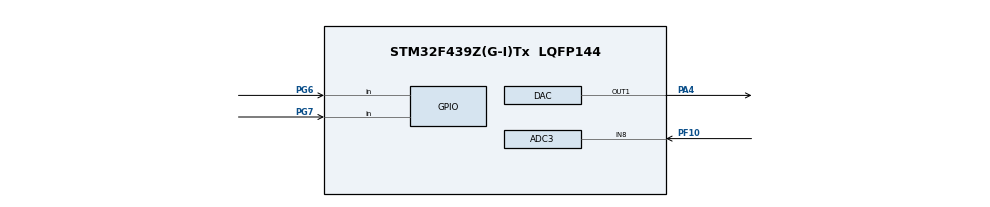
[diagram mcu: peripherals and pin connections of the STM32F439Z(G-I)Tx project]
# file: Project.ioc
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ADC3.Channel-0\#ChannelRegularConversion=ADC_CHANNEL_8
ADC3.ClockPrescaler=ADC_CLOCKPRESCALER_PCLK_DIV2
ADC3.ContinuousConvMode=ENABLE
ADC3.DMAContinuousRequests=ENABLE
ADC3.DataAlign=ADC_DATAALIGN_RIGHT
ADC3.DiscontinuousConvMode=DISABLE
ADC3.EOCSelection=EOC_SINGLE_CONV
ADC3.EnableAnalogWatchDog=false
ADC3.ExternalTrigConvEdge=ADC_EXTERNALTRIGCONVEDGE_NONE
ADC3.InjNumberOfConversion=0
ADC3.NbrOfConversion=1
ADC3.NbrOfConversionFlag=1
ADC3.Rank-0\#ChannelRegularConversion=1
ADC3.Resolution=ADC_RESOLUTION12b
ADC3.SamplingTime-0\#ChannelRegularConversion=ADC_SAMPLETIME_3CYCLES
ADC3.ScanConvMode=DISABLE
DAC.DAC_Trigger=DAC_TRIGGER_NONE
Dma.ADC3.0.Channel=DMA_CHANNEL_2
Dma.ADC3.0.Direction=DMA_PERIPH_TO_MEMORY
Dma.ADC3.0.FIFOMode=DMA_FIFOMODE_DISABLE
Dma.ADC3.0.FIFOThreshold=DMA_FIFO_THRESHOLD_FULL
Dma.ADC3.0.Instance=DMA2_Stream0
Dma.ADC3.0.MemBurst=DMA_MBURST_SINGLE
Dma.ADC3.0.MemDataAlignment=DMA_MDATAALIGN_WORD
Dma.ADC3.0.MemInc=DMA_MINC_DISABLE
Dma.ADC3.0.Mode=DMA_CIRCULAR
Dma.ADC3.0.PeriphBurst=DMA_PBURST_SINGLE
Dma.ADC3.0.PeriphDataAlignment=DMA_PDATAALIGN_WORD
Dma.ADC3.0.PeriphInc=DMA_PINC_DISABLE
Dma.ADC3.0.Priority=DMA_PRIORITY_HIGH
Dma.Request0=ADC3
Mcu.Family=STM32F4
Mcu.Name=STM32F439Z(G-I)Tx
Mcu.Package=LQFP144
NVIC.ADC_IRQn=true\:1\:0\:true
NVIC.DMA2_Stream0_IRQn=true\:3\:0\:true
NVIC.PriorityGroup=NVIC_PRIORITYGROUP_4
NVIC.TIM6_DAC_IRQn=true\:2\:0\:true
PA4.Signal=COMP_DAC1_group
PF10.Mode=IN8
PF10.Signal=ADC3_IN8
PG6.Signal=GPIO_Input
PG7.Signal=GPIO_Input
ProjectManager.TargetToolchain=EWARM
RCC.AHBFreq_Value=16000000
RCC.APB1Freq_Value=16000000
RCC.APB2Freq_Value=16000000
RCC.CortexFreq_Value=16000000
RCC.HSE_VALUE=25000000
RCC.HSI_VALUE=16000000
RCC.LSE_VALUE=32768
RCC.SYSCLKFreq_VALUE=16000000
RCC.VCOOutputFreq_Value=192000000
SH.COMP_DAC1_group.0=DAC_OUT1,DAC_OUT1
board=Project

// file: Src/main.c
/**
  ******************************************************************************
  * File Name          : main.c
  * Description        : Main program body
  ******************************************************************************
  *
  * COPYRIGHT(c) 2015 STMicroelectronics
  *
  * Redistribution and use in source and binary forms, with or without modification,
  * are permitted provided that the following conditions are met:
  *   1. Redistributions of source code must retain the above copyright notice,
  *      this list of conditions and the following disclaimer.
  *   2. Redistributions in binary form must reproduce the above copyright notice,
  *      this list of conditions and the following disclaimer in the documentation
  *      and/or other materials provided with the distribution.
  *   3. Neither the name of STMicroelectronics nor the names of its contributors
  *      may be used to endorse or promote products derived from this software
  *      without specific prior written permission.
  *
  * THIS SOFTWARE IS PROVIDED BY THE COPYRIGHT HOLDERS AND CONTRIBUTORS "AS IS"
  * AND ANY EXPRESS OR IMPLIED WARRANTIES, INCLUDING, BUT NOT LIMITED TO, THE
  * IMPLIED WARRANTIES OF MERCHANTABILITY AND FITNESS FOR A PARTICULAR PURPOSE ARE
  * DISCLAIMED. IN NO EVENT SHALL THE COPYRIGHT HOLDER OR CONTRIBUTORS BE LIABLE
  * FOR ANY DIRECT, INDIRECT, INCIDENTAL, SPECIAL, EXEMPLARY, OR CONSEQUENTIAL
  * DAMAGES (INCLUDING, BUT NOT LIMITED TO, PROCUREMENT OF SUBSTITUTE GOODS OR
  * SERVICES; LOSS OF USE, DATA, OR PROFITS; OR BUSINESS INTERRUPTION) HOWEVER
  * CAUSED AND ON ANY THEORY OF LIABILITY, WHETHER IN CONTRACT, STRICT LIABILITY,
  * OR TORT (INCLUDING NEGLIGENCE OR OTHERWISE) ARISING IN ANY WAY OUT OF THE USE
  * OF THIS SOFTWARE, EVEN IF ADVISED OF THE POSSIBILITY OF SUCH DAMAGE.
  *
  ******************************************************************************
  */
#include "stm32f4xx_hal.h"

ADC_HandleTypeDef hadc3;
DMA_HandleTypeDef hdma_adc3;

DAC_HandleTypeDef hdac;

/* USER CODE BEGIN PV */
/* Private variables ---------------------------------------------------------*/

/* USER CODE END PV */

void SystemClock_Config(void);
static void MX_GPIO_Init(void);
static void MX_DMA_Init(void);
static void MX_ADC3_Init(void);
static void MX_DAC_Init(void);

/* USER CODE BEGIN PFP */
/* Private function prototypes -----------------------------------------------*/

/* USER CODE END PFP */

int main(void)
{

  /* MCU Configuration----------------------------------------------------------*/

  /* Reset of all peripherals, Initializes the Flash interface and the Systick. */
  HAL_Init();

  /* Configure the system clock */
  SystemClock_Config();

  /* Initialize all configured peripherals */
  MX_GPIO_Init();
  MX_DMA_Init();
  MX_ADC3_Init();
  MX_DAC_Init();

  /* USER CODE BEGIN 2 */
  HAL_ADC_Start_DMA(&hadc3,(uint32_t*)0x40007408, 32);
  HAL_DAC_Start(&hdac, DAC_CHANNEL_1);

  /* USER CODE END 2 */

  /* Infinite loop */
  while (1)
  {

  }

}

/** System Clock Configuration
*/
void SystemClock_Config(void)
{

  RCC_OscInitTypeDef RCC_OscInitStruct;

  __PWR_CLK_ENABLE();

  __HAL_PWR_VOLTAGESCALING_CONFIG(PWR_REGULATOR_VOLTAGE_SCALE3);

  RCC_OscInitStruct.OscillatorType = RCC_OSCILLATORTYPE_HSI;
  RCC_OscInitStruct.HSIState = RCC_HSI_ON;
  RCC_OscInitStruct.HSICalibrationValue = 16;
  RCC_OscInitStruct.PLL.PLLState = RCC_PLL_NONE;
  HAL_RCC_OscConfig(&RCC_OscInitStruct);

  HAL_SYSTICK_Config(HAL_RCC_GetHCLKFreq()/1000);

  HAL_SYSTICK_CLKSourceConfig(SYSTICK_CLKSOURCE_HCLK);

}

/* ADC3 init function */
void MX_ADC3_Init(void)
{

  ADC_ChannelConfTypeDef sConfig;

    /**Configure the global features of the ADC (Clock, Resolution, Data Alignment and number of conversion)
    */
  hadc3.Instance = ADC3;
  hadc3.Init.ClockPrescaler = ADC_CLOCKPRESCALER_PCLK_DIV2;
  hadc3.Init.Resolution = ADC_RESOLUTION12b;
  hadc3.Init.ScanConvMode = DISABLE;
  hadc3.Init.ContinuousConvMode = ENABLE;
  hadc3.Init.DiscontinuousConvMode = DISABLE;
  hadc3.Init.ExternalTrigConvEdge = ADC_EXTERNALTRIGCONVEDGE_NONE;
  hadc3.Init.DataAlign = ADC_DATAALIGN_RIGHT;
  hadc3.Init.NbrOfConversion = 1;
  hadc3.Init.DMAContinuousRequests = ENABLE;
  hadc3.Init.EOCSelection = EOC_SINGLE_CONV;
  HAL_ADC_Init(&hadc3);

    /**Configure for the selected ADC regular channel its corresponding rank in the sequencer and its sample time.
    */
  sConfig.Channel = ADC_CHANNEL_8;
  sConfig.Rank = 1;
  sConfig.SamplingTime = ADC_SAMPLETIME_3CYCLES;
  HAL_ADC_ConfigChannel(&hadc3, &sConfig);

}

/* DAC init function */
void MX_DAC_Init(void)
{

  DAC_ChannelConfTypeDef sConfig;

    /**DAC Initialization
    */
  hdac.Instance = DAC;
  HAL_DAC_Init(&hdac);

    /**DAC channel OUT1 config
    */
  sConfig.DAC_Trigger = DAC_TRIGGER_NONE;
  sConfig.DAC_OutputBuffer = DAC_OUTPUTBUFFER_ENABLE;
  HAL_DAC_ConfigChannel(&hdac, &sConfig, DAC_CHANNEL_1);

}

void MX_DMA_Init(void)
{
  /* DMA controller clock enable */
  __DMA2_CLK_ENABLE();

  /* DMA interrupt init */
  HAL_NVIC_SetPriority(DMA2_Stream0_IRQn, 3, 0);
  HAL_NVIC_EnableIRQ(DMA2_Stream0_IRQn);

}

/** Configure pins as
        * Analog
        * Input
        * Output
        * EVENT_OUT
        * EXTI
*/
void MX_GPIO_Init(void)
{

  GPIO_InitTypeDef GPIO_InitStruct;

  /* GPIO Ports Clock Enable */
  __GPIOF_CLK_ENABLE();
  __GPIOA_CLK_ENABLE();
  __GPIOG_CLK_ENABLE();

  /*Configure GPIO pins : PG6 PG7 */
  GPIO_InitStruct.Pin = GPIO_PIN_6|GPIO_PIN_7;
  GPIO_InitStruct.Mode = GPIO_MODE_INPUT;
  GPIO_InitStruct.Pull = GPIO_NOPULL;
  HAL_GPIO_Init(GPIOG, &GPIO_InitStruct);

}

/************************ (C) COPYRIGHT STMicroelectronics *****END OF FILE****/
